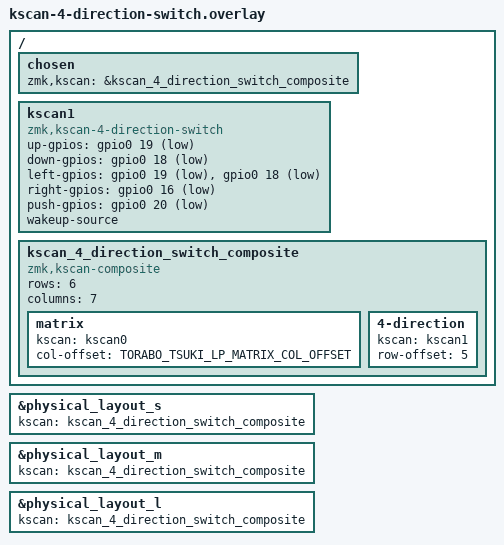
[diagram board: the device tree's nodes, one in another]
/{
    chosen {
        zmk,kscan = &kscan_4_direction_switch_composite;
    };

    kscan1: kscan1 {
        compatible = "zmk,kscan-4-direction-switch";

        up-gpios = <&gpio0 19 (GPIO_ACTIVE_LOW | GPIO_PULL_UP)>;
        down-gpios = <&gpio0 18 (GPIO_ACTIVE_LOW | GPIO_PULL_UP)>;
        left-gpios = <&gpio0 19 (GPIO_ACTIVE_LOW | GPIO_PULL_UP)>,
                      <&gpio0 18 (GPIO_ACTIVE_LOW | GPIO_PULL_UP)>;
        right-gpios = <&gpio0 16 (GPIO_ACTIVE_LOW | GPIO_PULL_UP)>;
        push-gpios = <&gpio0 20 (GPIO_ACTIVE_LOW | GPIO_PULL_UP)>;

        wakeup-source;
    };

    kscan_4_direction_switch_composite: kscan_4_direction_switch_composite {
        compatible = "zmk,kscan-composite";
        rows = <6>;
        columns = <7>;

        matrix {
            kscan = <&kscan0>;
            col-offset = <TORABO_TSUKI_LP_MATRIX_COL_OFFSET>;
        };

        4-direction {
            kscan = <&kscan1>;
            row-offset = <5>;
        };
    };
};

&physical_layout_s {
    kscan = <&kscan_4_direction_switch_composite>;
};

&physical_layout_m {
    kscan = <&kscan_4_direction_switch_composite>;
};

&physical_layout_l {
    kscan = <&kscan_4_direction_switch_composite>;
};
